# CAMERARX_CORE_0 register map
Vendor: Texas Instruments
Peripheral module from a debugger description file (folder DM50x).
Registers are 32-bit, read-write, reset 0x0 unless marked. A register's access mark holds for its fields unless they carry their own. Offsets are as the file gives them; lines under a group give offsets from that group; [hi:lo] are bit positions; {n}, {i} and the like mark numbered series; 'fields as' and 'values as' point back to an identical list; <NAME> marks a mode.

## CAMERARX_CORE_0
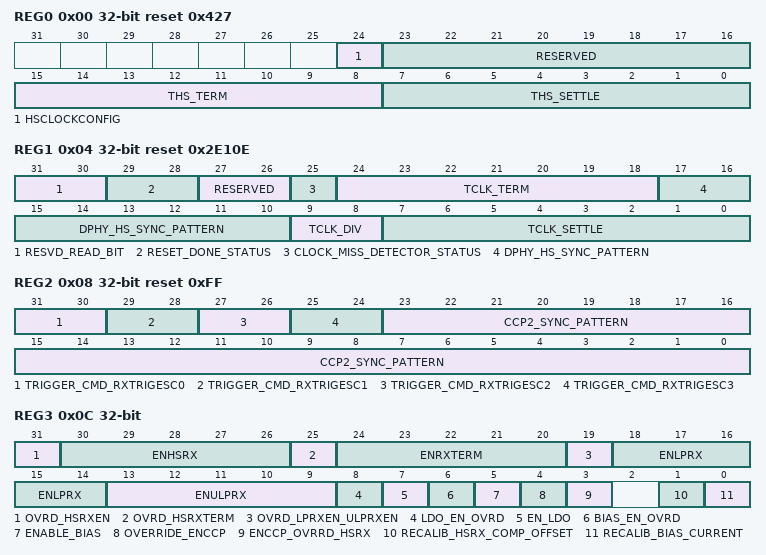
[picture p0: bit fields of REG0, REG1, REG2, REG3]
0x00 REG0 access not given reset 0x427 — First register
  [24] HSCLOCKCONFIG rw — Disable clock missing detector
  [23:16] RESERVED ro — Read returns zero
  [15:8] THS_TERM rw — THS_TERM timing parameter in multiples of DDR clock frequency. Effective time for enabling of termination = synchronizer delay + timer delay + LPRX delay + combinational routing delay ~ (1–2)* DDRCLK + THS-TERM + ~ (1 –15) ns. Programmed value = floor(20 ns/DDR_CLK), where DDR_CLK is the period of the CSI-2 I/O lane rate. Default value: 4 (for 400 MHz).
  [7:0] THS_SETTLE rw — THS_SETTLE timing parameter in multiples of DDR clock frequency. Effective THS_SETTLE seen on line (starting to look for sync pattern) = synchronizer delay + timer delay + LPRX delay + combinational routing delay – pipeline delay in HS data path ~ (1–2)* DDRCLK + THS-SETTLE + ~ (1–15) ns –1*DDRCLK. Programmed value = floor(105 ns/DDR_CLK) + 4, where DDR_CLK is the period of the CSI-2 I/O lane rate. Default value: 39 (for 400 MHz). Minimum supported THS-SETTLE programmed value = 3.
0x04 REG1 access not given reset 0x2E10E — Second register
  [31:30] RESVD_READ_BIT — Reserved bit (access NA)
  [29:28] RESET_DONE_STATUS ro — Reset done read bits.
  [27:26] RESERVED rw — Write 0 for future compatibility.
  [25] CLOCK_MISS_DETECTOR_STATUS ro — Clock missing detector status. Internal debug bit. 1: Error in clock missing detector.
    0=CLKMISS_0 (Clock missing detector successful Note: CLKMISS detector is likely to malfunction, if tclk-trail spec (60ns) is not honoured.)
  [24:18] TCLK_TERM rw — TCLK_TERM timing parameter in multiples of CTRLCLK Effective time for enabling of termination = synchronizer delay + timer delay + LPRX delay + combinational routing delay ~ (1–2)* CTRLCLK + TCLK_TERM + ~ (1–15) ns Programmed value = ceil(9.5 / CTRLCLK period) – 1 Default value : 0 (for 96 MHz)
  [17:10] DPHY_HS_SYNC_PATTERN rw — DPHY mode HS sync pattern in byte order (reverse of received order) See,
  [9:8] TCLK_DIV rw — CTRLCLK_DIV_FACTOR Divide factor for CTRLCLK for CLKMISS detector Programmed value = ceil (15ns/CTRLCLK Period) - 1 Default value: 1 (for 96 MHz) CLKMISS detection time = (5*TCLK_DIV+1)*(CTRLCLK period) &lt; 60ns Note: Only the CTRLCLK frequencies that satisfie above relationship are allowed. Typically, 96MHz will be used at CTRLCLK.
  [7:0] TCLK_SETTLE rw — TCLK_SETTLE timing parameter in multiples of CTRLCLK Clock Effective TCLK_SETTLE = synchronizer delay + timer delay + LPRX delay + combinational routing delay ~ (1–2)* CTRLCLK + Tclk-settle + ~ (1 –15) ns Programmed value = max[3, ceil(155 ns/CTRLCLK period) –1] Default value: 14 (for 96 MHz)
0x08 REG2 access per field reset 0xFF — Third register
  [31:30] TRIGGER_CMD_RXTRIGESC0 rw — Mapping of Trigger escape entry command to PPI output RXTRIGGERESC0 00 : '01100010' 01 : '01011101' 10: '00100001' 11: '10100000'
  [29:28] TRIGGER_CMD_RXTRIGESC1 rw — Mapping of Trigger escape entry command to PPI output RXTRIGGERESC1 00 : '01011101' 01 : '00100001' 10: '10100000' 11: '01100010'
  [27:26] TRIGGER_CMD_RXTRIGESC2 rw — Mapping of Trigger escape entry command to PPI output RXTRIGGERESC2 00 : '00100001' 01 : '01100010' 10: '01100010' 11: '01011101'
  [25:24] TRIGGER_CMD_RXTRIGESC3 rw — Mapping of Trigger escape entry command to PPI output RXTRIGGERESC3 00 : '10100000' 01 : '01100010' 10: '01011101' 11: '00100001'
  [23:0] CCP2_SYNC_PATTERN ro — CCP2 mode sync pattern in byte order (reverse of received order) See ,
0x0C REG3 (reset mask 0xFFFFFFDF) — Forth register
  [31] OVRD_HSRXEN — Override with register bit. 1:Override.0:Default
  [30:26] ENHSRX — HSRX Enable on LANE5-0.1:Enable. 0:Disable
  [25] OVRD_HSRXTERM — Override with register bit.1:Override. 0:Default
  [24:20] ENRXTERM — HS-RX Termination enable on LANE5-0.1:Enable.0:Default
  [19] OVRD_LPRXEN_ULPRXEN — Override LP-RX and ULP-RX Enable.1:Override. 0:Default
  [18:14] ENLPRX — Enable for LP-RX on LANE5-01 : Enable 0 : Disable
  [13:9] ENULPRX — Enable for ULP-RX on LANE5-01 : Enable 0 : Disable
  [8] LDO_EN_OVRD — LDO Enable Override.1:Override. 0:Default
  [7] EN_LDO — Enable LDO.1:Enable.0:Default
  [6] BIAS_EN_OVRD — BIAS Enable Override.1 :Override with register bit. 0:Default
  [5] ENABLE_BIAS — Enable BIAS.1:Enable 0:Disable
  [4] OVERRIDE_ENCCP — Override ENCCP to anatop.1: Override with register bit0:Default
  [3] ENCCP_OVRRD_HSRX — ENCCP override to HSRX.1: Enable0: Disable
  [1] RECALIB_HSRX_COMP_OFFSET — Recalibrate HS-RX comparator offset.Make this bit 0'1 to restart offset calibration. Usually offset calibration happens after PWRCMDON is received
  [0] RECALIB_BIAS_CURRENT — Recalibrate biasgen.Make this bit 0'1 to restart bias calibration. Biasgen trim code in efuse is overridden with new calibrated value till this bit is '1'.
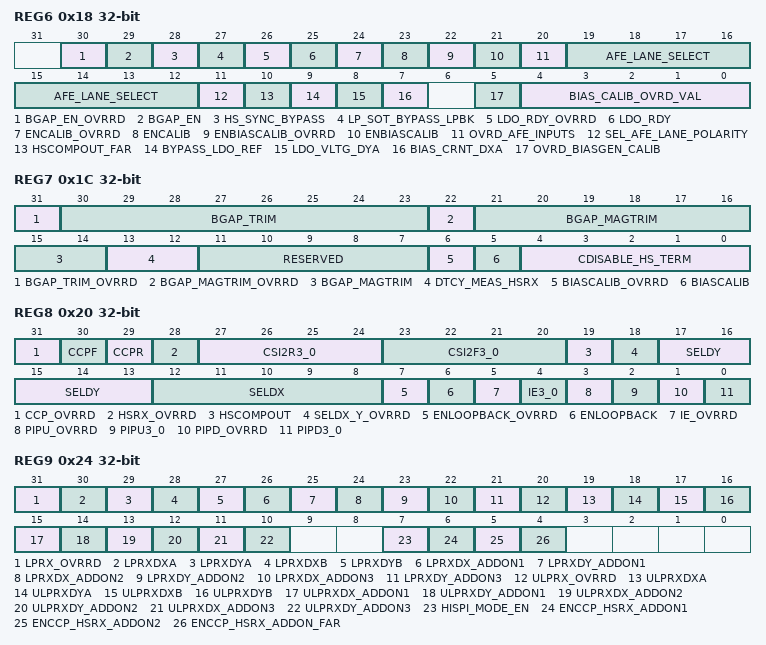
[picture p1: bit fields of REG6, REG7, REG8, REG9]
0x18 REG6 — Seventh register
  [30] BGAP_EN_OVRRD — BGAP enable override0: Default 1: Override bandgap enable with following register bit
  [29] BGAP_EN — BANDGAP enable0: Disable 1: enable
  [28] HS_SYNC_BYPASS — To bypass HS Sync sequence0: Normal 1: Bypass the HS Sync sequence
  [27] LP_SOT_BYPASS_LPBK — To bypass the LP SoT sequence in loopback mode0: Normal 1: Bypass the LP SoT sequence
  [26] LDO_RDY_OVRRD — LDO_RDY override0: Default 1: Override LDO_RDY with the following register bit
  [25] LDO_RDY — LDO_RDY makes internal LDO_RDY=1
  [24] ENCALIB_OVRRD — ENCALIB override0: Default 1: Override ENCALIBA and ENCALIBB with the following register bit
  [23] ENCALIB — ENCALIB* Override ENCALIBA and ENCALIBB with the register bit
  [22] ENBIASCALIB_OVRRD — ENBIASCALIB override0: Default 1: ENBIASCALIB override with the following bit
  [21] ENBIASCALIB — Override ENBIASCALIB with this register bit
  [20] OVRD_AFE_INPUTS — Override LANEENABLE and POLARITY AFE inputs.0:Normal. 1:Override
  [19:12] AFE_LANE_SELECT — Selects clock lane and data lane mapping for AFE. 8 bit LANESEL for AFE
  [11] SEL_AFE_LANE_POLARITY — Select AFE lane polarity. Polarity for clock lane in AFE
  [10] HSCOMPOUT_FAR — Select FAR lane HSCOMP output to HSCOMOOUT in AFE.
  [9] BYPASS_LDO_REF — 0:Normal.1:Bypass reference with VDD
  [8] LDO_VLTG_DYA — Observe LDO voltage on DYA pad.0:Normal. 1:Observe LDO voltage
  [7] BIAS_CRNT_DXA — Observe bias current on DXA pad.0:Normal. 1:Observe bias current
  [5] OVRD_BIASGEN_CALIB — 1:Override the EFUSE bits with register value.0:Default
  [4:0] BIAS_CALIB_OVRD_VAL — Biasgen calibration code override value
0x1C REG7 — Eight register
  [31] BGAP_TRIM_OVRRD — Bandgap trim bits override 0: Normal (default mode) 1: Override Bandgap trim bits with SCP register bits
  [30:23] BGAP_TRIM — Bandgap trim bits 00000000 : Minimum bandgap voltage 11111111 : Maximum bandgap voltage
  [22] BGAP_MAGTRIM_OVRRD — Bandgap magnitude trim bits override0: Normal (default mode) 1: Override Bandgap trim bits with SCP register bits
  [21:14] BGAP_MAGTRIM — Bandgap magnitude trim bits00000000 : Minimum bandgap voltage 11111111 : Maximum bandgap voltage
  [13:12] DTCY_MEAS_HSRX — Duty cycle measurement in HSRX mode00: Default 11: TBD
  [11:7] RESERVED — Write 0 for future compatibility
  [6] BIASCALIB_OVRRD — BIASCALIB override 0: Default 1: Override BIASCALIB with the register bit[5]
  [5] BIASCALIB — BIASCALIB bit from SCP reg
  [4:0] CDISABLE_HS_TERM — Disable HS Termination 00000: Normal 11111: Disable Lane4,3,2,1,0 resp
0x20 REG8 — Ninth register
  [31] CCP_OVRRD — CCP override0: Normal 1: Override CCP outputs with the register bits
  [30] CCPF — Override CCPF from analog with this register bit
  [29] CCPR — Override CCPR from analog with this register bit
  [28] HSRX_OVRRD — HSRX override 0: Normal 1: Override HSRX signals with the following register bits
  [27:24] CSI2R3_0 — Override CSI2R[3:0] for 4 lanes from analog with these register bits
  [23:20] CSI2F3_0 — Override CSI2F[3:0] for 4 lanes from analog with these register bits
  [19] HSCOMPOUT — Override HSCOMPOUT from analog with this register bit
  [18] SELDX_Y_OVRRD — SELDX*/Y* override0: Overrides the control to bypass of LPRX delay on DX/DY pads depending on testmode_sel_reg[6] and WPI_PMT[0] for DX pads and WPI_PMT[1] for DY pads. 1: Override the control to bypass the LPRX delay on DY/DX pads with the following register bits for all lanes
  [17:13] SELDY — SELDY*controls bypass of LPRY delay on DY pads (5 lanes) Bit Mapping: 17 -&gt; ADDON3 16 -&gt; ADDON2 17 -&gt; LaneB 14 -&gt; LaneA 13 -&gt; ADDON1
  [12:8] SELDX — SELDX*controls bypass of LPRX delay on DX pads (5 lanes) Bit Mapping: 12 -&gt; ADDON3 11 -&gt; ADDON2 10 -&gt; LaneB 9 -&gt; LaneA 8 -&gt; ADDON1
  [7] ENLOOPBACK_OVRRD — ENLOOPBACK Override0: Normal 1: Override ENLOOPBACK transmitter enable (in self or internal loopback mode) with register bit[6]
  [6] ENLOOPBACK — ENLOOPBACK transmitter enable (in self or internal loopback mode) from SCP register bit
  [5] IE_OVRRD — IE override 0: Normal 1: Override IE (4 lanes) with the following register bit
  [4] IE3_0 — Override IE[3:0] (4 lanes) with this single bit.
  [3] PIPU_OVRRD — PIPU override0: Normal 1: Override PIPU (4 lanes) with the following register bit
  [2] PIPU3_0 — Override PIPU[3:0] (4 lanes) with this single bit.
  [1] PIPD_OVRRD — PIPD override 0: Normal 1: Override PIPD (4 lanes) with the following register bit
  [0] PIPD3_0 — Override PIPD[3:0] (4 lanes) with this single bit.
0x24 REG9 — Tenth register
  [31] LPRX_OVRRD — LPRX override0: Normal (defautlt mode) 1: Override the LPRXD* signals with SCP register bits
  [30] LPRXDXA — Bypass LPRXD* comparator output with this bit
  [29] LPRXDYA — Bypass LPRXD* comparator output with this bit
  [28] LPRXDXB — Bypass LPRXD* comparator output with this bit
  [27] LPRXDYB — Bypass LPRXD* comparator output with this bit
  [26] LPRXDX_ADDON1 — Bypass LPRXD* comparator output with this bit
  [25] LPRXDY_ADDON1 — Bypass LPRXD* comparator output with this bit
  [24] LPRXDX_ADDON2 — Bypass LPRXD* comparator output with this bit
  [23] LPRXDY_ADDON2 — Bypass LPRXD* comparator output with this bit
  [22] LPRXDX_ADDON3 — Bypass LPRXD* comparator output with this bit
  [21] LPRXDY_ADDON3 — Bypass LPRXD* comparator output with this bit
  [20] ULPRX_OVRRD — ULPRX Override0: Normal (default mode) 1: Override the ULPRXD* signals with SCP register bits
  [19] ULPRXDXA — Bypass ULPRXD* comparator output with this bit
  [18] ULPRXDYA — Bypass ULPRXD* comparator output with this bit
  [17] ULPRXDXB — Bypass ULPRXD* comparator output with this bit
  [16] ULPRXDYB — Bypass ULPRXD* comparator output with this bit
  [15] ULPRXDX_ADDON1 — Bypass ULPRXD* comparator output with this bit
  [14] ULPRXDY_ADDON1 — Bypass ULPRXD* comparator output with this bit
  [13] ULPRXDX_ADDON2 — Bypass ULPRXD* comparator output with this bit
  [12] ULPRXDY_ADDON2 — Bypass ULPRXD* comparator output with this bit
  [11] ULPRXDX_ADDON3 — Bypass ULPRXD* comparator output with this bit
  [10] ULPRXDY_ADDON3 — Bypass ULPRXD* comparator output with this bit
  [7] HISPI_MODE_EN — This bit enables the PHY in HiSPi mode0: HiSPi mode disabled (Default) 1: HiSPI mode enabled
  [6] ENCCP_HSRX_ADDON1 — ENCCP override to HSRX of ADDON1.1: Enable0: Disable
  [5] ENCCP_HSRX_ADDON2 — ENCCP override to HSRX of ADDON2.1: Enable 0: Disable
  [4] ENCCP_HSRX_ADDON_FAR — ENCCP override to HSRX of ADDON_FAR.1: Enable0: Disable
0x28 REG10 — Eleventh register
  [15:0] SPAREIN_ANATOP — Sparein AnatopThese bits are directly mapped to SPAREIN* pins of Analog (both LDO and Core voltage domains) and ADDONs for future use.
